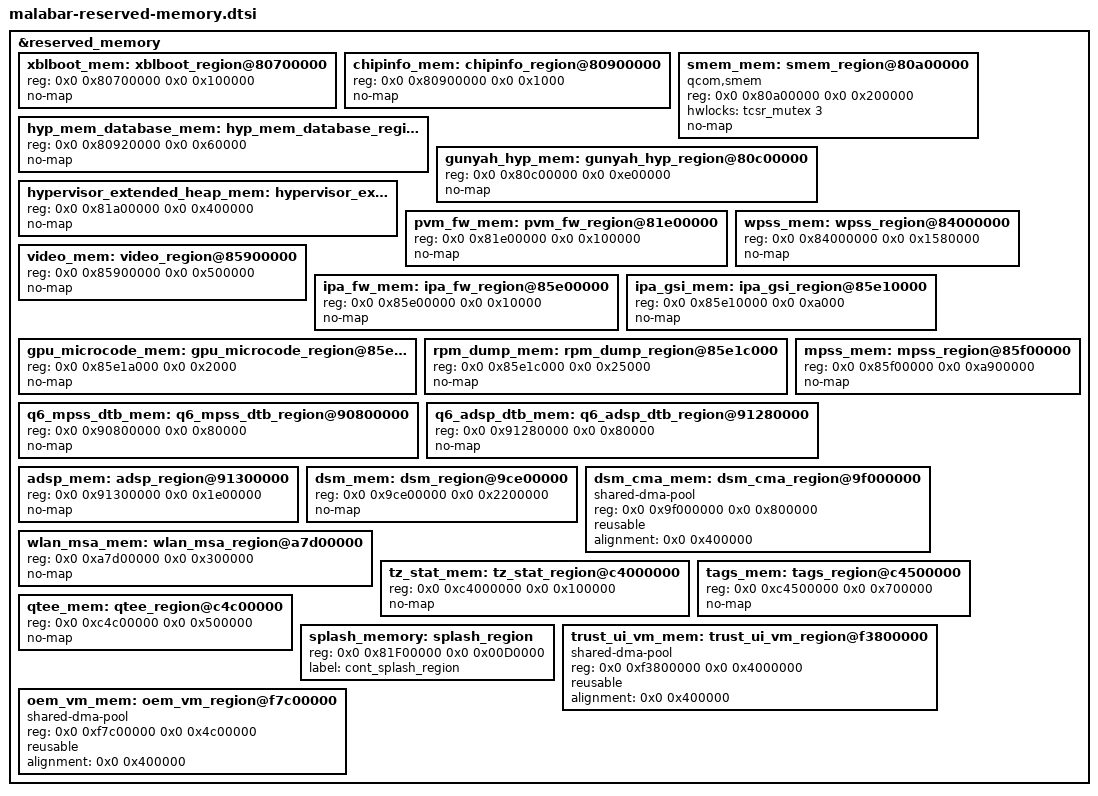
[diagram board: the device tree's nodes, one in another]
// SPDX-License-Identifier: BSD-3-Clause
/*
 * Copyright (c) Qualcomm Technologies, Inc. and/or its subsidiaries.
 */

&reserved_memory {
	#address-cells = <2>;
	#size-cells = <2>;
	ranges;

	xblboot_mem: xblboot_region@80700000 {
		reg = <0x0 0x80700000 0x0 0x100000>;
		no-map;
	};

	chipinfo_mem: chipinfo_region@80900000 {
		reg = <0x0 0x80900000 0x0 0x1000>;
		no-map;
	};

	hyp_mem_database_mem: hyp_mem_database_region@80920000 {
		reg = <0x0 0x80920000 0x0 0x60000>;
		no-map;
	};

	/* secdata region at 0x809ff000 can be reused by apps */

	smem_mem: smem_region@80a00000 {
		reg = <0x0 0x80a00000 0x0 0x200000>;
		compatible = "qcom,smem";
		hwlocks = <&tcsr_mutex 3>;
		no-map;
	};

	gunyah_hyp_mem: gunyah_hyp_region@80c00000 {
		reg = <0x0 0x80c00000 0x0 0xe00000>;
		no-map;
	};

	hypervisor_extended_heap_mem: hypervisor_extended_heap_region@81a00000 {
		reg = <0x0 0x81a00000 0x0 0x400000>;
		no-map;
	};

	pvm_fw_mem: pvm_fw_region@81e00000 {
		reg = <0x0 0x81e00000 0x0 0x100000>;
		no-map;
	};

	/* splash_screen region at 0x81f00000 will change dynamically */

	wpss_mem: wpss_region@84000000 {
		reg = <0x0 0x84000000 0x0 0x1580000>;
		no-map;
	};

	video_mem: video_region@85900000 {
		reg = <0x0 0x85900000 0x0 0x500000>;
		no-map;
	};

	ipa_fw_mem: ipa_fw_region@85e00000 {
		reg = <0x0 0x85e00000 0x0 0x10000>;
		no-map;
	};

	ipa_gsi_mem: ipa_gsi_region@85e10000 {
		reg = <0x0 0x85e10000 0x0 0xa000>;
		no-map;
	};

	gpu_microcode_mem: gpu_microcode_region@85e1a000 {
		reg = <0x0 0x85e1a000 0x0 0x2000>;
		no-map;
	};

	rpm_dump_mem: rpm_dump_region@85e1c000 {
		reg = <0x0 0x85e1c000 0x0 0x25000>;
		no-map;
	};

	mpss_mem: mpss_region@85f00000 {
		reg = <0x0 0x85f00000 0x0 0xa900000>;
		no-map;
	};

	q6_mpss_dtb_mem: q6_mpss_dtb_region@90800000 {
		reg = <0x0 0x90800000 0x0 0x80000>;
		no-map;
	};

	q6_adsp_dtb_mem: q6_adsp_dtb_region@91280000 {
		reg = <0x0 0x91280000 0x0 0x80000>;
		no-map;
	};

	adsp_mem: adsp_region@91300000 {
		reg = <0x0 0x91300000 0x0 0x1e00000>;
		no-map;
	};

	dsm_mem: dsm_region@9ce00000 {
		reg = <0x0 0x9ce00000 0x0 0x2200000>;
		no-map;
	};

	dsm_cma_mem: dsm_cma_region@9f000000 {
		compatible = "shared-dma-pool";
		reg = <0x0 0x9f000000 0x0 0x800000>;
		reusable;
		alignment = <0x0 0x400000>;
	};

	/* UEFI region at 0x9f800000 is reclaimed by Linux */

	wlan_msa_mem: wlan_msa_region@a7d00000 {
		reg = <0x0 0xa7d00000 0x0 0x300000>;
		no-map;
	};

	/* Linux kernel image is loaded at 0xa8000000 */

	tz_stat_mem: tz_stat_region@c4000000 {
		reg = <0x0 0xc4000000 0x0 0x100000>;
		no-map;
	};

	tags_mem: tags_region@c4500000 {
		reg = <0x0 0xc4500000 0x0 0x700000>;
		no-map;
	};

	qtee_mem: qtee_region@c4c00000 {
		reg = <0x0 0xc4c00000 0x0 0x500000>;
		no-map;
	};

	splash_memory: splash_region {
		reg = <0x0 0x81F00000 0x0 0x00D0000>;
		label = "cont_splash_region";
	};
	/* trusted_apps* region at 0xc5100000 will change dynamically */

	/* vm_kernel_memoem_configurable_mem was split into trust_ui_vm_mem & oem_vm_mem below */
	trust_ui_vm_mem: trust_ui_vm_region@f3800000 { // VM_KERNEL_MEM
		compatible = "shared-dma-pool";
		reg = <0x0 0xf3800000 0x0 0x4000000>;
		reusable;
		alignment = <0x0 0x400000>;
	};

	oem_vm_mem: oem_vm_region@f7c00000 {
		compatible = "shared-dma-pool";
		reg = <0x0 0xf7c00000 0x0 0x4c00000>;
		reusable;
		alignment = <0x0 0x400000>;
	};
};
